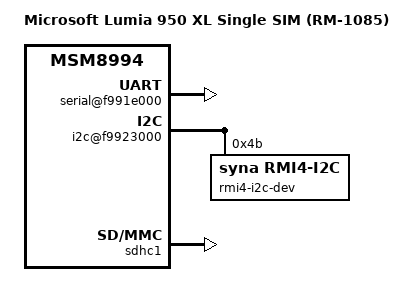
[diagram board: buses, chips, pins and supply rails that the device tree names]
/* Copyright (c) 2016, The Linux Foundation. All rights reserved.
 * Copyright (c) 2018, Bingxing Wang. All rights reserved.
 *
 * This program is free software; you can redistribute it and/or modify
 * it under the terms of the GNU General Public License version 2 and
 * only version 2 as published by the Free Software Foundation.
 *
 * This program is distributed in the hope that it will be useful,
 * but WITHOUT ANY WARRANTY; without even the implied warranty of
 * MERCHANTABILITY or FITNESS FOR A PARTICULAR PURPOSE.  See the
 * GNU General Public License for more details.
 */

 /dts-v1/;

#include "msm8994.dtsi"

/ {
	model = "Microsoft Lumia 950 XL Single SIM (RM-1085)";
	compatible = "msft,rm-1085", "qcom,msm8994";
	/* Loading the dt via GRUB2. Not really care about this. */
	qcom,board-id = <8 0>;

	aliases {
		serial0 = &blsp1_uart2;
		i2c1 = &blsp1_i2c1;
	};

	soc {
		serial@f991e000 {
			status = "okay";
			pinctrl-names = "default", "sleep";
			pinctrl-0 = <&blsp1_uart2_default>;
			pinctrl-1 = <&blsp1_uart2_sleep>;
		};

		i2c@f9923000 {
			status = "okay";

			rmi4-i2c-dev@4b {
				compatible = "syna,rmi4-i2c";
				reg = <0x4b>;
				#address-cells = <1>;
				#size-cells = <0>;

				rmi4-f01@1 {
					reg = <0x01>;
					syna,nosleep-mode = <1>;
				};

				rmi4-f12@12 {
					reg = <0x12>;
					syna,sensor-type = <1>;
					syna,clip-x-low = <0>;
					syna,clip-x-high = <1440>;
					syna,clip-y-low = <0>;
					syna,clip-y-high = <2660>;
				};
			};
		};
	};
};

&sdhc1 {
	status = "okay";
};
